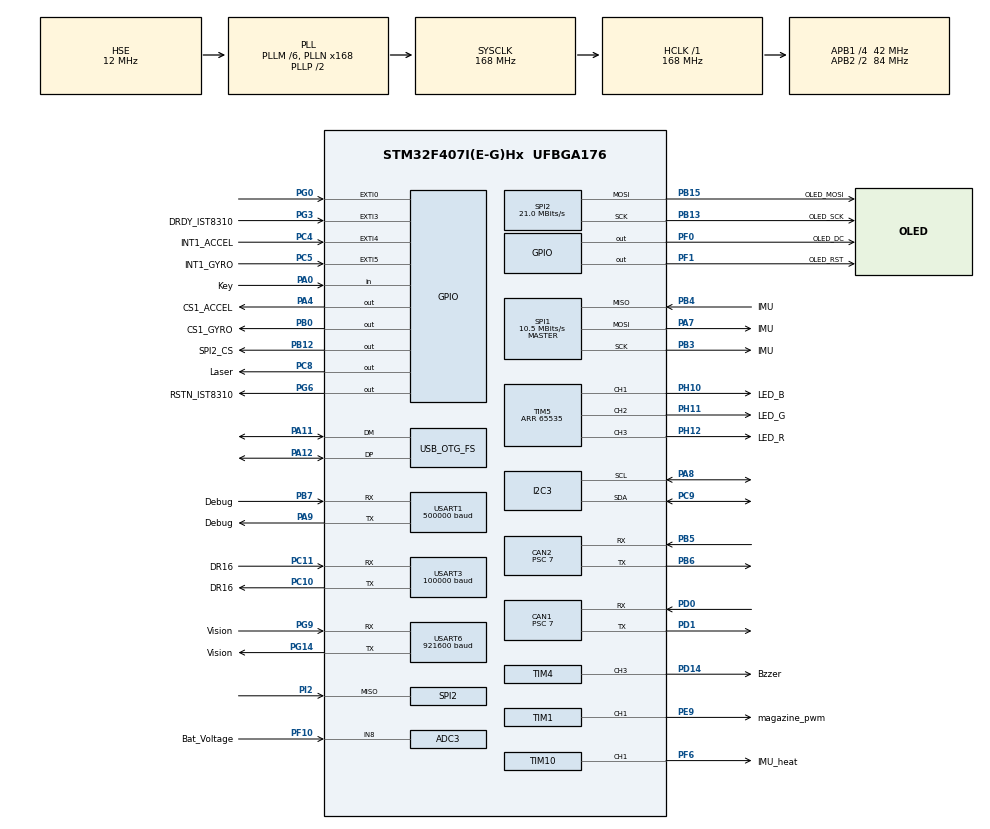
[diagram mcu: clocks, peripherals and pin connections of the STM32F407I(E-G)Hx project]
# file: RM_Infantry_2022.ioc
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ADC1.Channel-0\#ChannelRegularConversion=ADC_CHANNEL_VREFINT
ADC1.NbrOfConversionFlag=1
ADC1.Rank-0\#ChannelRegularConversion=1
ADC1.SamplingTime-0\#ChannelRegularConversion=ADC_SAMPLETIME_3CYCLES
ADC1.master=1
ADC3.Channel-0\#ChannelRegularConversion=ADC_CHANNEL_8
ADC3.NbrOfConversionFlag=1
ADC3.Rank-0\#ChannelRegularConversion=1
ADC3.SamplingTime-0\#ChannelRegularConversion=ADC_SAMPLETIME_3CYCLES
CAN1.ABOM=ENABLE
CAN1.AWUM=ENABLE
CAN1.BS1=CAN_BS1_3TQ
CAN1.BS2=CAN_BS2_2TQ
CAN1.CalculateTimeQuantum=166.66666666666669
CAN1.NART=ENABLE
CAN1.Prescaler=7
CAN1.TXFP=ENABLE
CAN2.ABOM=ENABLE
CAN2.AWUM=ENABLE
CAN2.BS1=CAN_BS1_3TQ
CAN2.BS2=CAN_BS2_2TQ
CAN2.CalculateTimeQuantum=166.66666666666669
CAN2.NART=ENABLE
CAN2.Prescaler=7
CAN2.TXFP=ENABLE
Dma.Request0=USART3_RX
Dma.Request1=SPI1_TX
Dma.Request2=SPI1_RX
Dma.Request3=USART6_RX
Dma.Request4=USART6_TX
Dma.Request5=USART1_TX
Dma.Request6=USART1_RX
Dma.SPI1_RX.2.Direction=DMA_PERIPH_TO_MEMORY
Dma.SPI1_RX.2.FIFOMode=DMA_FIFOMODE_DISABLE
Dma.SPI1_RX.2.Instance=DMA2_Stream0
Dma.SPI1_RX.2.MemDataAlignment=DMA_MDATAALIGN_BYTE
Dma.SPI1_RX.2.MemInc=DMA_MINC_ENABLE
Dma.SPI1_RX.2.Mode=DMA_NORMAL
Dma.SPI1_RX.2.PeriphDataAlignment=DMA_PDATAALIGN_BYTE
Dma.SPI1_RX.2.PeriphInc=DMA_PINC_DISABLE
Dma.SPI1_RX.2.Priority=DMA_PRIORITY_VERY_HIGH
Dma.SPI1_TX.1.Direction=DMA_MEMORY_TO_PERIPH
Dma.SPI1_TX.1.FIFOMode=DMA_FIFOMODE_DISABLE
Dma.SPI1_TX.1.Instance=DMA2_Stream3
Dma.SPI1_TX.1.MemDataAlignment=DMA_MDATAALIGN_BYTE
Dma.SPI1_TX.1.MemInc=DMA_MINC_ENABLE
Dma.SPI1_TX.1.Mode=DMA_NORMAL
Dma.SPI1_TX.1.PeriphDataAlignment=DMA_PDATAALIGN_BYTE
Dma.SPI1_TX.1.PeriphInc=DMA_PINC_DISABLE
Dma.SPI1_TX.1.Priority=DMA_PRIORITY_HIGH
Dma.USART1_RX.6.Direction=DMA_PERIPH_TO_MEMORY
Dma.USART1_RX.6.FIFOMode=DMA_FIFOMODE_DISABLE
Dma.USART1_RX.6.Instance=DMA2_Stream2
Dma.USART1_RX.6.MemDataAlignment=DMA_MDATAALIGN_BYTE
Dma.USART1_RX.6.MemInc=DMA_MINC_ENABLE
Dma.USART1_RX.6.Mode=DMA_CIRCULAR
Dma.USART1_RX.6.PeriphDataAlignment=DMA_PDATAALIGN_BYTE
Dma.USART1_RX.6.PeriphInc=DMA_PINC_DISABLE
Dma.USART1_RX.6.Priority=DMA_PRIORITY_MEDIUM
Dma.USART1_TX.5.Direction=DMA_MEMORY_TO_PERIPH
Dma.USART1_TX.5.FIFOMode=DMA_FIFOMODE_DISABLE
Dma.USART1_TX.5.Instance=DMA2_Stream7
Dma.USART1_TX.5.MemDataAlignment=DMA_MDATAALIGN_BYTE
Dma.USART1_TX.5.MemInc=DMA_MINC_ENABLE
Dma.USART1_TX.5.Mode=DMA_CIRCULAR
Dma.USART1_TX.5.PeriphDataAlignment=DMA_PDATAALIGN_BYTE
Dma.USART1_TX.5.PeriphInc=DMA_PINC_DISABLE
Dma.USART1_TX.5.Priority=DMA_PRIORITY_MEDIUM
Dma.USART3_RX.0.Direction=DMA_PERIPH_TO_MEMORY
Dma.USART3_RX.0.FIFOMode=DMA_FIFOMODE_DISABLE
Dma.USART3_RX.0.Instance=DMA1_Stream1
Dma.USART3_RX.0.MemDataAlignment=DMA_MDATAALIGN_BYTE
Dma.USART3_RX.0.MemInc=DMA_MINC_ENABLE
Dma.USART3_RX.0.Mode=DMA_CIRCULAR
Dma.USART3_RX.0.PeriphDataAlignment=DMA_PDATAALIGN_BYTE
Dma.USART3_RX.0.PeriphInc=DMA_PINC_DISABLE
Dma.USART3_RX.0.Priority=DMA_PRIORITY_LOW
Dma.USART6_RX.3.Direction=DMA_PERIPH_TO_MEMORY
Dma.USART6_RX.3.FIFOMode=DMA_FIFOMODE_DISABLE
Dma.USART6_RX.3.Instance=DMA2_Stream1
Dma.USART6_RX.3.MemDataAlignment=DMA_MDATAALIGN_BYTE
Dma.USART6_RX.3.MemInc=DMA_MINC_ENABLE
Dma.USART6_RX.3.Mode=DMA_CIRCULAR
Dma.USART6_RX.3.PeriphDataAlignment=DMA_PDATAALIGN_BYTE
Dma.USART6_RX.3.PeriphInc=DMA_PINC_DISABLE
Dma.USART6_RX.3.Priority=DMA_PRIORITY_MEDIUM
Dma.USART6_TX.4.Direction=DMA_MEMORY_TO_PERIPH
Dma.USART6_TX.4.FIFOMode=DMA_FIFOMODE_DISABLE
Dma.USART6_TX.4.Instance=DMA2_Stream6
Dma.USART6_TX.4.MemDataAlignment=DMA_MDATAALIGN_BYTE
Dma.USART6_TX.4.MemInc=DMA_MINC_ENABLE
Dma.USART6_TX.4.Mode=DMA_NORMAL
Dma.USART6_TX.4.PeriphDataAlignment=DMA_PDATAALIGN_BYTE
Dma.USART6_TX.4.PeriphInc=DMA_PINC_DISABLE
Dma.USART6_TX.4.Priority=DMA_PRIORITY_MEDIUM
FREERTOS.INCLUDE_eTaskGetState=1
FREERTOS.INCLUDE_uxTaskGetStackHighWaterMark=1
FREERTOS.INCLUDE_vTaskCleanUpResources=1
FREERTOS.INCLUDE_vTaskDelayUntil=1
FREERTOS.INCLUDE_xTaskGetCurrentTaskHandle=1
FREERTOS.INCLUDE_xTaskGetHandle=1
FREERTOS.Queues01=xQueueCAN1_Recv,20,CanRxMsg_t,0,Dynamic,NULL,NULL;xQueueCAN2_Recv,20,CanRxMsg_t,0,Dynamic,NULL,NULL
FREERTOS.Tasks01=Activate_Task,0,128,User_SystemInit_Task,Default,NULL,Dynamic,NULL,NULL
FREERTOS.configTOTAL_HEAP_SIZE=24567
FREERTOS.configUSE_TIMERS=1
I2C3.I2C_Mode=I2C_Fast
Mcu.Family=STM32F4
Mcu.Name=STM32F407I(E-G)Hx
Mcu.Package=UFBGA176
NVIC.CAN1_RX0_IRQn=true\:5\:0\:true\:false\:true\:false\:true\:true
NVIC.CAN2_RX0_IRQn=true\:5\:0\:true\:false\:true\:false\:true\:true
NVIC.DMA1_Stream1_IRQn=true\:5\:0\:true\:false\:true\:false\:false\:true
NVIC.DMA2_Stream0_IRQn=true\:5\:0\:true\:false\:false\:true\:false\:false
NVIC.DMA2_Stream1_IRQn=true\:5\:0\:true\:false\:true\:true\:false\:true
NVIC.DMA2_Stream2_IRQn=true\:0\:0\:false\:false\:true\:true\:false\:true
NVIC.DMA2_Stream3_IRQn=true\:5\:0\:true\:false\:false\:true\:false\:false
NVIC.DMA2_Stream6_IRQn=true\:5\:0\:true\:false\:true\:true\:false\:true
NVIC.DMA2_Stream7_IRQn=true\:5\:0\:true\:false\:true\:true\:false\:true
NVIC.EXTI0_IRQn=true\:6\:0\:true\:false\:true\:false\:true\:true
NVIC.EXTI3_IRQn=true\:5\:0\:true\:false\:true\:false\:true\:true
NVIC.EXTI4_IRQn=true\:5\:0\:true\:false\:true\:false\:true\:true
NVIC.EXTI9_5_IRQn=true\:5\:0\:true\:false\:true\:false\:true\:true
NVIC.OTG_FS_IRQn=true\:0\:0\:false\:false\:true\:false\:false\:true
NVIC.PriorityGroup=NVIC_PRIORITYGROUP_4
NVIC.TIM6_DAC_IRQn=true\:0\:0\:false\:false\:true\:false\:false\:true
NVIC.TimeBase=TIM6_DAC_IRQn
NVIC.TimeBaseIP=TIM6
NVIC.USART1_IRQn=true\:0\:0\:false\:false\:true\:false\:true\:true
NVIC.USART3_IRQn=true\:5\:0\:true\:false\:true\:false\:true\:true
NVIC.USART6_IRQn=true\:5\:0\:true\:false\:true\:true\:true\:true
PA0-WKUP.GPIO_Label=Key
PA0-WKUP.Signal=GPIO_Input
PA11.Mode=Device_Only
PA11.Signal=USB_OTG_FS_DM
PA12.Mode=Device_Only
PA12.Signal=USB_OTG_FS_DP
PA13.Mode=Serial_Wire
PA13.Signal=SYS_JTMS-SWDIO
PA14.Mode=Serial_Wire
PA14.Signal=SYS_JTCK-SWCLK
PA4.GPIO_Label=CS1_ACCEL
PA4.GPIO_PuPd=GPIO_PULLUP
PA4.GPIO_Speed=GPIO_SPEED_FREQ_HIGH
PA4.PinState=GPIO_PIN_SET
PA4.Signal=GPIO_Output
PA7.GPIO_Label=IMU
PA7.GPIO_PuPd=GPIO_PULLUP
PA7.Mode=Full_Duplex_Master
PA7.Signal=SPI1_MOSI
PA8.Mode=I2C
PA8.Signal=I2C3_SCL
PA9.GPIO_Label=Debug
PA9.Mode=Asynchronous
PA9.Signal=USART1_TX
PB0.GPIO_Label=CS1_GYRO
PB0.GPIO_PuPd=GPIO_PULLUP
PB0.GPIO_Speed=GPIO_SPEED_FREQ_HIGH
PB0.PinState=GPIO_PIN_SET
PB0.Signal=GPIO_Output
PB12.GPIO_Label=SPI2_CS
PB12.GPIO_PuPd=GPIO_PULLUP
PB12.GPIO_Speed=GPIO_SPEED_FREQ_MEDIUM
PB12.PinState=GPIO_PIN_SET
PB12.Signal=GPIO_Output
PB13.GPIO_Label=OLED_SCK
PB13.Mode=Full_Duplex_Master
PB13.Signal=SPI2_SCK
PB15.GPIO_Label=OLED_MOSI
PB15.Mode=Full_Duplex_Master
PB15.Signal=SPI2_MOSI
PB3.GPIO_Label=IMU
PB3.GPIO_PuPd=GPIO_PULLUP
PB3.Mode=Full_Duplex_Master
PB3.Signal=SPI1_SCK
PB4.GPIO_Label=IMU
PB4.GPIO_PuPd=GPIO_PULLUP
PB4.Mode=Full_Duplex_Master
PB4.Signal=SPI1_MISO
PB5.Mode=Slave
PB5.Signal=CAN2_RX
PB6.Mode=Slave
PB6.Signal=CAN2_TX
PB7.GPIO_Label=Debug
PB7.Mode=Asynchronous
PB7.Signal=USART1_RX
PC10.GPIO_Label=DR16
PC10.Mode=Asynchronous
PC10.Signal=USART3_TX
PC11.GPIO_Label=DR16
PC11.Mode=Asynchronous
PC11.Signal=USART3_RX
PC4.GPIO_Label=INT1_ACCEL
PC4.GPIO_PuPd=GPIO_PULLUP
PC4.Signal=GPXTI4
PC5.GPIO_Label=INT1_GYRO
PC5.GPIO_PuPd=GPIO_PULLUP
PC5.Signal=GPXTI5
PC8.GPIO_Label=Laser
PC8.Signal=GPIO_Output
PC9.Mode=I2C
PC9.Signal=I2C3_SDA
PD0.Mode=Master
PD0.Signal=CAN1_RX
PD1.Mode=Master
PD1.Signal=CAN1_TX
PD14.GPIO_Label=Bzzer
PD14.Signal=S_TIM4_CH3
PE9.GPIO_Label=magazine_pwm
PE9.Signal=S_TIM1_CH1
PF0.GPIO_Label=OLED_DC
PF0.Signal=GPIO_Output
PF1.GPIO_Label=OLED_RST
PF1.Signal=GPIO_Output
PF10.GPIO_Label=Bat_Voltage
PF10.Mode=IN8
PF10.Signal=ADC3_IN8
PF6.GPIO_Label=IMU_heat
PF6.GPIO_PuPd=GPIO_PULLUP
PF6.GPIO_Speed=GPIO_SPEED_FREQ_HIGH
PF6.Signal=S_TIM10_CH1
PG0.GPIO_PuPd=GPIO_PULLUP
PG0.Signal=GPXTI0
PG14.GPIO_Label=Vision
PG14.Mode=Asynchronous
PG14.Signal=USART6_TX
PG3.GPIO_Label=DRDY_IST8310
PG3.GPIO_PuPd=GPIO_PULLUP
PG3.Signal=GPXTI3
PG6.GPIO_Label=RSTN_IST8310
PG6.GPIO_PuPd=GPIO_PULLUP
PG6.GPIO_Speed=GPIO_SPEED_FREQ_MEDIUM
PG6.PinState=GPIO_PIN_SET
PG6.Signal=GPIO_Output
PG9.GPIO_Label=Vision
PG9.Mode=Asynchronous
PG9.Signal=USART6_RX
PH0-OSC_IN.Mode=HSE-External-Oscillator
PH0-OSC_IN.Signal=RCC_OSC_IN
PH1-OSC_OUT.Mode=HSE-External-Oscillator
PH1-OSC_OUT.Signal=RCC_OSC_OUT
PH10.GPIO_Label=LED_B
PH10.GPIO_PuPd=GPIO_PULLUP
PH10.GPIO_Speed=GPIO_SPEED_FREQ_HIGH
PH10.Signal=S_TIM5_CH1
PH11.GPIO_Label=LED_G
PH11.GPIO_PuPd=GPIO_PULLUP
PH11.GPIO_Speed=GPIO_SPEED_FREQ_HIGH
PH11.Signal=S_TIM5_CH2
PH12.GPIO_Label=LED_R
PH12.GPIO_PuPd=GPIO_PULLUP
PH12.GPIO_Speed=GPIO_SPEED_FREQ_HIGH
PH12.Signal=S_TIM5_CH3
PI2.Mode=Full_Duplex_Master
PI2.Signal=SPI2_MISO
ProjectManager.HeapSize=0x2000
ProjectManager.StackSize=0x2000
ProjectManager.TargetToolchain=MDK-ARM V5.27
RCC.48MHZClocksFreq_Value=48000000
RCC.AHBFreq_Value=168000000
RCC.APB1CLKDivider=RCC_HCLK_DIV4
RCC.APB1Freq_Value=42000000
RCC.APB1TimFreq_Value=84000000
RCC.APB2CLKDivider=RCC_HCLK_DIV2
RCC.APB2Freq_Value=84000000
RCC.APB2TimFreq_Value=168000000
RCC.CortexFreq_Value=168000000
RCC.HCLKFreq_Value=168000000
RCC.HSE_VALUE=12000000
RCC.HSI_VALUE=16000000
RCC.LSE_VALUE=32768
RCC.PLLM=6
RCC.PLLN=168
RCC.PLLQ=7
RCC.SYSCLKFreq_VALUE=168000000
RCC.SYSCLKSource=RCC_SYSCLKSOURCE_PLLCLK
RCC.VCOOutputFreq_Value=336000000
SH.S_TIM10_CH1.0=TIM10_CH1,PWM Generation1 CH1
SH.S_TIM1_CH1.0=TIM1_CH1,PWM Generation1 CH1
SH.S_TIM4_CH3.0=TIM4_CH3,PWM Generation3 CH3
SH.S_TIM5_CH1.0=TIM5_CH1,PWM Generation1 CH1
SH.S_TIM5_CH2.0=TIM5_CH2,PWM Generation2 CH2
SH.S_TIM5_CH3.0=TIM5_CH3,PWM Generation3 CH3
SPI1.BaudRatePrescaler=SPI_BAUDRATEPRESCALER_8
SPI1.CLKPhase=SPI_PHASE_2EDGE
SPI1.CLKPolarity=SPI_POLARITY_HIGH
SPI1.CalculateBaudRate=10.5 MBits/s
SPI1.Direction=SPI_DIRECTION_2LINES
SPI1.Mode=SPI_MODE_MASTER
SPI1.VirtualType=VM_MASTER
SPI2.CalculateBaudRate=21.0 MBits/s
SPI2.Direction=SPI_DIRECTION_2LINES
SPI2.Mode=SPI_MODE_MASTER
SPI2.VirtualType=VM_MASTER
TIM1.Channel-PWM\ Generation1\ CH1=TIM_CHANNEL_1
TIM1.Period=19999
TIM1.Prescaler=83
TIM1.Pulse-PWM\ Generation1\ CH1=0
TIM10.Channel=TIM_CHANNEL_1
TIM10.Period=4999
TIM10.Pulse=0
TIM4.Channel-PWM\ Generation3\ CH3=TIM_CHANNEL_3
TIM4.Period=370
TIM4.Prescaler=130
TIM4.Pulse-PWM\ Generation3\ CH3=10
TIM5.Channel-PWM\ Generation1\ CH1=TIM_CHANNEL_1
TIM5.Channel-PWM\ Generation2\ CH2=TIM_CHANNEL_2
TIM5.Channel-PWM\ Generation3\ CH3=TIM_CHANNEL_3
TIM5.Period=65535
USART1.BaudRate=500000
USART1.VirtualMode=VM_ASYNC
USART3.BaudRate=100000
USART3.Parity=PARITY_EVEN
USART3.VirtualMode=VM_ASYNC
USART3.WordLength=WORDLENGTH_9B
USART6.BaudRate=921600
USART6.VirtualMode=VM_ASYNC
USB_DEVICE.CLASS_NAME_FS=CDC
USB_DEVICE.VirtualMode-CDC_FS=Cdc
USB_DEVICE.VirtualModeFS=Cdc_FS
USB_OTG_FS.VirtualMode=Device_Only
VP_ADC1_Vref_Input.Mode=IN-Vrefint
VP_FREERTOS_VS_CMSIS_V1.Mode=CMSIS_V1
VP_SYS_VS_tim6.Mode=TIM6
VP_TIM10_VS_ClockSourceINT.Mode=Enable_Timer
VP_TIM1_VS_ClockSourceINT.Mode=Internal
VP_TIM4_VS_ClockSourceINT.Mode=Internal
VP_TIM5_VS_ClockSourceINT.Mode=Internal
VP_USB_DEVICE_VS_USB_DEVICE_CDC_FS.Mode=CDC_FS
board=custom

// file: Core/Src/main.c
/* USER CODE BEGIN Header */
/**
  ******************************************************************************
  * @file           : main.c
  * @brief          : Main program body
  ******************************************************************************
  * @attention
  *
  * <h2><center>&copy; Copyright (c) 2022 STMicroelectronics.
  * All rights reserved.</center></h2>
  *
  * This software component is licensed by ST under BSD 3-Clause license,
  * the "License"; You may not use this file except in compliance with the
  * License. You may obtain a copy of the License at:
  *                        opensource.org/licenses/BSD-3-Clause
  *
  ******************************************************************************
  */
/* USER CODE END Header */
#include "main.h"
#include "cmsis_os.h"
#include "adc.h"
#include "can.h"
#include "dma.h"
#include "i2c.h"
#include "spi.h"
#include "tim.h"
#include "usart.h"
#include "usb_device.h"
#include "gpio.h"

/* USER CODE BEGIN Includes */
//test==================================================================================
//test2+++++++++++++++++++++++++++++++++++++++++++++++++++++++++++++++++++++++++++++++++
#include "System_Config.h"
/* USER CODE END Includes */

void SystemClock_Config(void);
void MX_FREERTOS_Init(void);

int main(void)
{

  /* MCU Configuration--------------------------------------------------------*/

  /* Reset of all peripherals, Initializes the Flash interface and the Systick. */
  HAL_Init();

  /* Configure the system clock */
  SystemClock_Config();

  /* Initialize all configured peripherals */
  MX_GPIO_Init();
  MX_DMA_Init();
  MX_CAN1_Init();
  MX_CAN2_Init();
  MX_USART3_UART_Init();
  MX_TIM4_Init();
  MX_TIM5_Init();
  MX_USART1_UART_Init();
  MX_SPI1_Init();
  MX_TIM10_Init();
  MX_I2C3_Init();
  MX_USART6_UART_Init();
  MX_TIM1_Init();
  MX_SPI2_Init();
  MX_ADC1_Init();
  MX_ADC3_Init();
  /* USER CODE BEGIN 2 */
	GPIO_Init();
  User_System_Init();
  /* USER CODE END 2 */

  /* Call init function for freertos objects (in freertos.c) */
  MX_FREERTOS_Init();
  /* Start scheduler */
  osKernelStart();

  /* We should never get here as control is now taken by the scheduler */
  /* Infinite loop */
  while (1)
  {

  }
}

void SystemClock_Config(void)
{
  RCC_OscInitTypeDef RCC_OscInitStruct = {0};
  RCC_ClkInitTypeDef RCC_ClkInitStruct = {0};

  /** Configure the main internal regulator output voltage
  */
  __HAL_RCC_PWR_CLK_ENABLE();
  __HAL_PWR_VOLTAGESCALING_CONFIG(PWR_REGULATOR_VOLTAGE_SCALE1);
  /** Initializes the RCC Oscillators according to the specified parameters
  * in the RCC_OscInitTypeDef structure.
  */
  RCC_OscInitStruct.OscillatorType = RCC_OSCILLATORTYPE_HSE;
  RCC_OscInitStruct.HSEState = RCC_HSE_ON;
  RCC_OscInitStruct.PLL.PLLState = RCC_PLL_ON;
  RCC_OscInitStruct.PLL.PLLSource = RCC_PLLSOURCE_HSE;
  RCC_OscInitStruct.PLL.PLLM = 6;
  RCC_OscInitStruct.PLL.PLLN = 168;
  RCC_OscInitStruct.PLL.PLLP = RCC_PLLP_DIV2;
  RCC_OscInitStruct.PLL.PLLQ = 7;
  if (HAL_RCC_OscConfig(&RCC_OscInitStruct) != HAL_OK)
  {
    Error_Handler();
  }
  /** Initializes the CPU, AHB and APB buses clocks
  */
  RCC_ClkInitStruct.ClockType = RCC_CLOCKTYPE_HCLK|RCC_CLOCKTYPE_SYSCLK
                              |RCC_CLOCKTYPE_PCLK1|RCC_CLOCKTYPE_PCLK2;
  RCC_ClkInitStruct.SYSCLKSource = RCC_SYSCLKSOURCE_PLLCLK;
  RCC_ClkInitStruct.AHBCLKDivider = RCC_SYSCLK_DIV1;
  RCC_ClkInitStruct.APB1CLKDivider = RCC_HCLK_DIV4;
  RCC_ClkInitStruct.APB2CLKDivider = RCC_HCLK_DIV2;

  if (HAL_RCC_ClockConfig(&RCC_ClkInitStruct, FLASH_LATENCY_5) != HAL_OK)
  {
    Error_Handler();
  }
}

void HAL_TIM_PeriodElapsedCallback(TIM_HandleTypeDef *htim)
{
  if (htim->Instance == TIM6) {
    HAL_IncTick();
  }
}

void Error_Handler(void)
{
}

/************************ (C) COPYRIGHT STMicroelectronics *****END OF FILE****/
